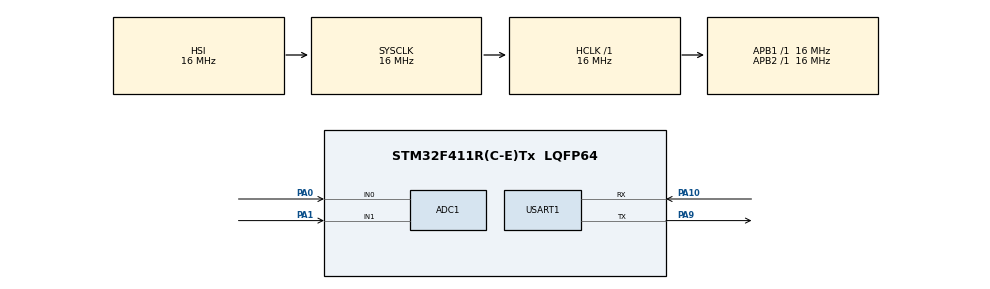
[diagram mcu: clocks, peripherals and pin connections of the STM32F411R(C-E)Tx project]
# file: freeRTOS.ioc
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ADC1.Channel-0\#ChannelRegularConversion=ADC_CHANNEL_0
ADC1.Channel-1\#ChannelRegularConversion=ADC_CHANNEL_1
ADC1.ClockPrescaler=ADC_CLOCK_SYNC_PCLK_DIV8
ADC1.ContinuousConvMode=ENABLE
ADC1.DMAContinuousRequests=ENABLE
ADC1.NbrOfConversion=2
ADC1.NbrOfConversionFlag=1
ADC1.Rank-0\#ChannelRegularConversion=1
ADC1.Rank-1\#ChannelRegularConversion=2
ADC1.SamplingTime-0\#ChannelRegularConversion=ADC_SAMPLETIME_480CYCLES
ADC1.SamplingTime-1\#ChannelRegularConversion=ADC_SAMPLETIME_480CYCLES
ADC1.ScanConvMode=ENABLE
ADC1.master=1
Dma.ADC1.0.Direction=DMA_PERIPH_TO_MEMORY
Dma.ADC1.0.FIFOMode=DMA_FIFOMODE_DISABLE
Dma.ADC1.0.Instance=DMA2_Stream0
Dma.ADC1.0.MemDataAlignment=DMA_MDATAALIGN_HALFWORD
Dma.ADC1.0.MemInc=DMA_MINC_ENABLE
Dma.ADC1.0.Mode=DMA_CIRCULAR
Dma.ADC1.0.PeriphDataAlignment=DMA_PDATAALIGN_HALFWORD
Dma.ADC1.0.PeriphInc=DMA_PINC_DISABLE
Dma.ADC1.0.Priority=DMA_PRIORITY_LOW
Dma.Request0=ADC1
FREERTOS.Tasks01=TaskA,24,128,functionA,Default,NULL,Dynamic,NULL,NULL;TaskB,8,128,functionB,Default,NULL,Dynamic,NULL,NULL
FREERTOS.configUSE_NEWLIB_REENTRANT=1
Mcu.Family=STM32F4
Mcu.Name=STM32F411R(C-E)Tx
Mcu.Package=LQFP64
NVIC.DMA2_Stream0_IRQn=true\:5\:0\:false\:false\:true\:true\:false\:true\:true
NVIC.PriorityGroup=NVIC_PRIORITYGROUP_4
PA0-WKUP.Signal=ADCx_IN0
PA1.Signal=ADCx_IN1
PA10.Mode=Asynchronous
PA10.Signal=USART1_RX
PA9.Mode=Asynchronous
PA9.Signal=USART1_TX
ProjectManager.HeapSize=0x200
ProjectManager.StackSize=0x400
ProjectManager.TargetToolchain=STM32CubeIDE
RCC.AHBFreq_Value=16000000
RCC.APB1Freq_Value=16000000
RCC.APB2Freq_Value=16000000
RCC.CortexFreq_Value=16000000
RCC.HSE_VALUE=25000000
RCC.HSI_VALUE=16000000
RCC.LSE_VALUE=32768
RCC.SYSCLKFreq_VALUE=16000000
RCC.VCOOutputFreq_Value=192000000
SH.ADCx_IN0.0=ADC1_IN0,IN0
SH.ADCx_IN1.0=ADC1_IN1,IN1
USART1.VirtualMode=VM_ASYNC
VP_FREERTOS_VS_CMSIS_V2.Mode=CMSIS_V2
board=custom

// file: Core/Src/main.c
/* USER CODE BEGIN Header */
/**
  ******************************************************************************
  * @file           : main.c
  * @brief          : Main program body
  ******************************************************************************
  * @attention
  *
  * Copyright (c) 2023 STMicroelectronics.
  * All rights reserved.
  *
  * This software is licensed under terms that can be found in the LICENSE file
  * in the root directory of this software component.
  * If no LICENSE file comes with this software, it is provided AS-IS.
  *
  ******************************************************************************
  */
/* USER CODE END Header */
#include "main.h"
#include "cmsis_os.h"

/* USER CODE BEGIN Includes */
#include "uart.h"
/* USER CODE END Includes */

ADC_HandleTypeDef hadc1;
DMA_HandleTypeDef hdma_adc1;

UART_HandleTypeDef huart1;

/* Definitions for TaskA */
osThreadId_t TaskAHandle;
const osThreadAttr_t TaskA_attributes = {
  .name = "TaskA",
  .stack_size = 128 * 4,
  .priority = (osPriority_t) osPriorityNormal,
};
/* Definitions for TaskB */
osThreadId_t TaskBHandle;
const osThreadAttr_t TaskB_attributes = {
  .name = "TaskB",
  .stack_size = 128 * 4,
  .priority = (osPriority_t) osPriorityLow,
};

void SystemClock_Config(void);
static void MX_GPIO_Init(void);
static void MX_DMA_Init(void);
static void MX_USART1_UART_Init(void);
static void MX_ADC1_Init(void);
void functionA(void *argument);
void functionB(void *argument);

/* USER CODE BEGIN 0 */
uint16_t valueAdc[500];
/* USER CODE END 0 */

int main(void)
{

  /* MCU Configuration--------------------------------------------------------*/

  /* Reset of all peripherals, Initializes the Flash interface and the Systick. */
  HAL_Init();

  /* Configure the system clock */
  SystemClock_Config();

  /* Initialize all configured peripherals */
  MX_GPIO_Init();
  MX_DMA_Init();
  MX_USART1_UART_Init();
  MX_ADC1_Init();
  /* USER CODE BEGIN 2 */
  HAL_ADC_Start_DMA(&hadc1, valueAdc, 500);
  /* USER CODE END 2 */

  /* Init scheduler */
  osKernelInitialize();
/* USER CODE BEGIN Header */
/**
  ******************************************************************************
  * @file           : main.c
  * @brief          : Main program body
  ******************************************************************************
  * @attention
  *
  * Copyright (c) 2023 STMicroelectronics.
  * All rights reserved.
  *
  * This software is licensed under terms that can be found in the LICENSE file
  * in the root directory of this software component.
  * If no LICENSE file comes with this software, it is provided AS-IS.
  *
  ******************************************************************************
  */
  TaskAHandle = osThreadNew(functionA, 0, &TaskA_attributes);
  TaskBHandle = osThreadNew(functionB, 0, &TaskB_attributes);
/* USER CODE END Header */

  /* Start scheduler */
  osKernelStart();

  /* We should never get here as control is now taken by the scheduler */
  /* Infinite loop */
  while (1)
  {

  }
}

void SystemClock_Config(void)
{
  RCC_OscInitTypeDef RCC_OscInitStruct = {0};
  RCC_ClkInitTypeDef RCC_ClkInitStruct = {0};

  /** Configure the main internal regulator output voltage
  */
  __HAL_RCC_PWR_CLK_ENABLE();
  __HAL_PWR_VOLTAGESCALING_CONFIG(PWR_REGULATOR_VOLTAGE_SCALE1);

  /** Initializes the RCC Oscillators according to the specified parameters
  * in the RCC_OscInitTypeDef structure.
  */
  RCC_OscInitStruct.OscillatorType = RCC_OSCILLATORTYPE_HSI;
  RCC_OscInitStruct.HSIState = RCC_HSI_ON;
  RCC_OscInitStruct.HSICalibrationValue = RCC_HSICALIBRATION_DEFAULT;
  RCC_OscInitStruct.PLL.PLLState = RCC_PLL_NONE;
  if (HAL_RCC_OscConfig(&RCC_OscInitStruct) != HAL_OK)
  {
    Error_Handler();
  }

  /** Initializes the CPU, AHB and APB buses clocks
  */
  RCC_ClkInitStruct.ClockType = RCC_CLOCKTYPE_HCLK|RCC_CLOCKTYPE_SYSCLK
                              |RCC_CLOCKTYPE_PCLK1|RCC_CLOCKTYPE_PCLK2;
  RCC_ClkInitStruct.SYSCLKSource = RCC_SYSCLKSOURCE_HSI;
  RCC_ClkInitStruct.AHBCLKDivider = RCC_SYSCLK_DIV1;
  RCC_ClkInitStruct.APB1CLKDivider = RCC_HCLK_DIV1;
  RCC_ClkInitStruct.APB2CLKDivider = RCC_HCLK_DIV1;

  if (HAL_RCC_ClockConfig(&RCC_ClkInitStruct, FLASH_LATENCY_0) != HAL_OK)
  {
    Error_Handler();
  }
}

static void MX_ADC1_Init(void)
{

  ADC_ChannelConfTypeDef sConfig = {0};

  /** Configure the global features of the ADC (Clock, Resolution, Data Alignment and number of conversion)
  */
  hadc1.Instance = ADC1;
  hadc1.Init.ClockPrescaler = ADC_CLOCK_SYNC_PCLK_DIV2;
  hadc1.Init.Resolution = ADC_RESOLUTION_12B;
  hadc1.Init.ScanConvMode = DISABLE;
  hadc1.Init.ContinuousConvMode = ENABLE;
  hadc1.Init.DiscontinuousConvMode = DISABLE;
  hadc1.Init.ExternalTrigConvEdge = ADC_EXTERNALTRIGCONVEDGE_NONE;
  hadc1.Init.ExternalTrigConv = ADC_SOFTWARE_START;
  hadc1.Init.DataAlign = ADC_DATAALIGN_RIGHT;
  hadc1.Init.NbrOfConversion = 1;
  hadc1.Init.DMAContinuousRequests = ENABLE;
  hadc1.Init.EOCSelection = ADC_EOC_SINGLE_CONV;
  if (HAL_ADC_Init(&hadc1) != HAL_OK)
  {
    Error_Handler();
  }

  /** Configure for the selected ADC regular channel its corresponding rank in the sequencer and its sample time.
  */
  sConfig.Channel = ADC_CHANNEL_0;
  sConfig.Rank = 1;
  sConfig.SamplingTime = ADC_SAMPLETIME_3CYCLES;
  if (HAL_ADC_ConfigChannel(&hadc1, &sConfig) != HAL_OK)
  {
    Error_Handler();
  }

}

static void MX_USART1_UART_Init(void)
{

  huart1.Instance = USART1;
  huart1.Init.BaudRate = 115200;
  huart1.Init.WordLength = UART_WORDLENGTH_8B;
  huart1.Init.StopBits = UART_STOPBITS_1;
  huart1.Init.Parity = UART_PARITY_NONE;
  huart1.Init.Mode = UART_MODE_TX_RX;
  huart1.Init.HwFlowCtl = UART_HWCONTROL_NONE;
  huart1.Init.OverSampling = UART_OVERSAMPLING_16;
  if (HAL_UART_Init(&huart1) != HAL_OK)
  {
    Error_Handler();
  }

}

static void MX_DMA_Init(void)
{

  /* DMA controller clock enable */
  __HAL_RCC_DMA2_CLK_ENABLE();

  /* DMA interrupt init */
  /* DMA2_Stream0_IRQn interrupt configuration */
  HAL_NVIC_SetPriority(DMA2_Stream0_IRQn, 5, 0);
  HAL_NVIC_EnableIRQ(DMA2_Stream0_IRQn);

}

static void MX_GPIO_Init(void)
{

  /* GPIO Ports Clock Enable */
  __HAL_RCC_GPIOA_CLK_ENABLE();

}

void functionA(void *argument)
{
  /* USER CODE BEGIN 5 */

  /* Infinite loop */
  for(;;)
  {
  	for(int i = 0; i < 500; i++) {
			printf("%d\n", valueAdc[i]);
			osDelay(1);
  	}
  }
  /* USER CODE END 5 */
}

void functionB(void *argument)
{
  /* USER CODE BEGIN functionB */

  /* Infinite loop */
	// PA0 : 서미스터
	// PA1 : CDS
  for(;;)
  {
    osDelay(1000);
  }
  /* USER CODE END functionB */
}

void Error_Handler(void)
{
  __disable_irq();
  while (1)
  {
  }
}
